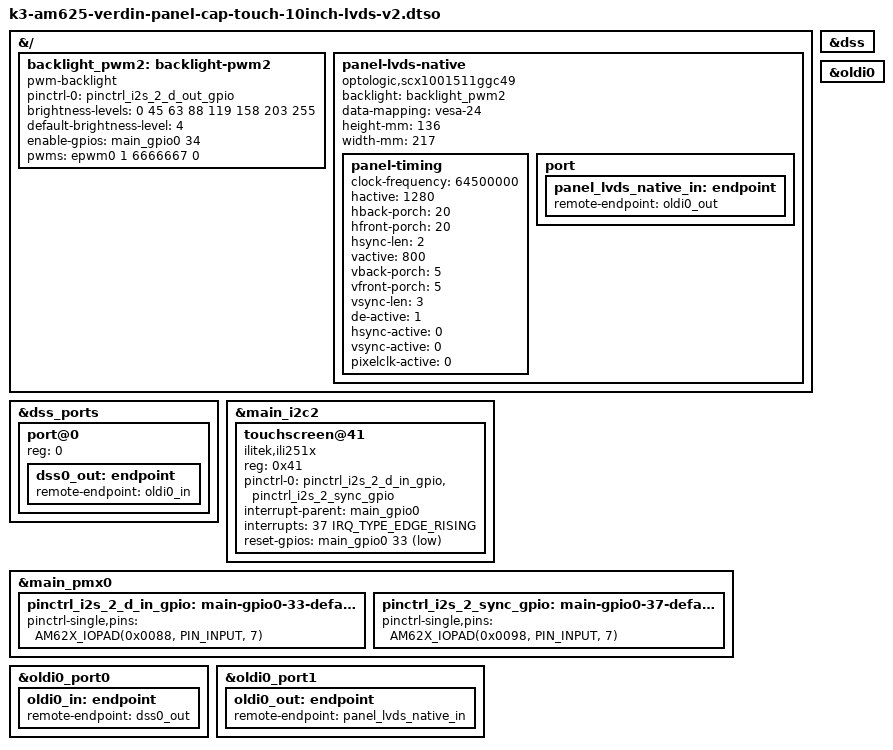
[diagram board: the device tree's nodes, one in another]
// SPDX-License-Identifier: GPL-2.0-or-later OR MIT
/*
 * Copyright (c) Toradex
 *
 * Toradex Capacitive Touch Display 10.1" V2 connected via Verdin AM62 OLDI
 * on carrier boards with a Toradex standard LVDS display connector
 *
 * https://developer.toradex.com/hardware/accessories/displays/capacitive-touch-display-101inch-lvds
 * https://www.toradex.com/accessories/capacitive-touch-display-10.1-inch-lvds
 */

/dts-v1/;
/plugin/;

#include <dt-bindings/gpio/gpio.h>
#include <dt-bindings/interrupt-controller/irq.h>
#include <dt-bindings/pwm/pwm.h>
#include "k3-pinctrl.h"

&{/} {
	backlight_pwm2: backlight-pwm2 {
		compatible = "pwm-backlight";
		pinctrl-names = "default";
		pinctrl-0 = <&pinctrl_i2s_2_d_out_gpio>;
		brightness-levels = <0 45 63 88 119 158 203 255>;
		default-brightness-level = <4>;
		/* Verdin I2S_2_D_OUT as GPIO (SODIMM 46) */
		enable-gpios = <&main_gpio0 34 GPIO_ACTIVE_HIGH>;
		/* Verdin PWM_2 (SODIMM 16) */
		pwms = <&epwm0 1 6666667 0>;
	};

	panel-lvds-native {
		compatible = "optologic,scx1001511ggc49", "panel-lvds";
		backlight = <&backlight_pwm2>;
		data-mapping = "vesa-24";
		height-mm = <136>;
		width-mm = <217>;

		panel-timing {
			clock-frequency = <64500000>;
			hactive = <1280>;
			hback-porch = <20>;
			hfront-porch = <20>;
			hsync-len = <2>;
			vactive = <800>;
			vback-porch = <5>;
			vfront-porch = <5>;
			vsync-len = <3>;
			de-active = <1>;
			hsync-active = <0>;
			vsync-active = <0>;
			pixelclk-active = <0>;
		};

		port {
			panel_lvds_native_in: endpoint {
				remote-endpoint = <&oldi0_out>;
			};
		};
	};
};

&dss {
	status = "okay";
};

&dss_ports {
	#address-cells = <1>;
	#size-cells = <0>;

	/* DSS VP1: internal DPI output to OLDIx */
	port@0 {
		reg = <0>;

		dss0_out: endpoint {
			remote-endpoint = <&oldi0_in>;
		};
	};
};

/* Verdin I2C_2_DSI */
&main_i2c2 {
	#address-cells = <1>;
	#size-cells = <0>;

	touchscreen@41 {
		compatible = "ilitek,ili251x";
		reg = <0x41>;
		pinctrl-names = "default";
		pinctrl-0 = <&pinctrl_i2s_2_d_in_gpio>,
			    <&pinctrl_i2s_2_sync_gpio>;
		/* Verdin I2S_2_SYNC as GPIO (SODIMM 44) */
		interrupt-parent = <&main_gpio0>;
		interrupts = <37 IRQ_TYPE_EDGE_RISING>;
		/* Verdin I2S_2_D_IN as GPIO(SODIMM 48) */
		reset-gpios = <&main_gpio0 33 GPIO_ACTIVE_LOW>;
	};
};

&main_pmx0 {
	pinctrl_i2s_2_d_in_gpio: main-gpio0-33-default-pins {
		pinctrl-single,pins = <
			AM62X_IOPAD(0x0088, PIN_INPUT, 7) /* (L24) GPMC0_OEn_REn.GPIO0_33 */ /* SODIMM 48 */
		>;
	};

	pinctrl_i2s_2_sync_gpio: main-gpio0-37-default-pins {
		pinctrl-single,pins = <
			AM62X_IOPAD(0x0098, PIN_INPUT, 7) /* (U23) GPMC0_WAIT0.GPIO0_37 */ /* SODIMM 44 */
		>;
	};
};

&oldi0 {
	status = "okay";
};

&oldi0_port0 {
	oldi0_in: endpoint {
		remote-endpoint = <&dss0_out>;
	};
};

&oldi0_port1 {
	oldi0_out: endpoint {
		remote-endpoint = <&panel_lvds_native_in>;
	};
};
